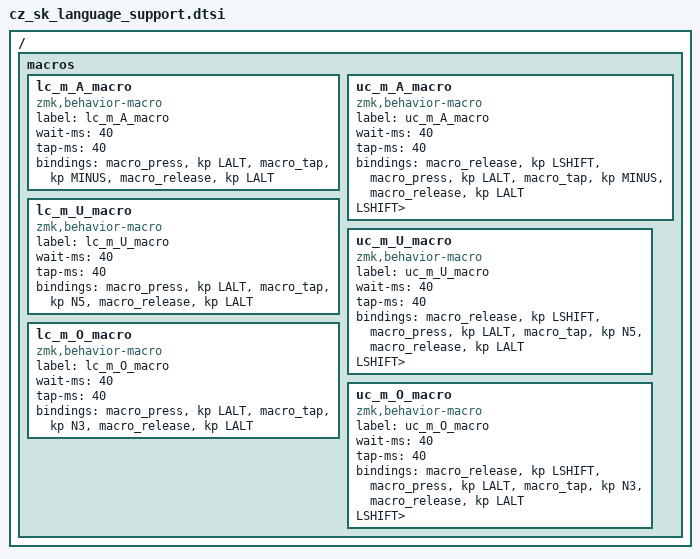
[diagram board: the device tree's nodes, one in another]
#include <dt-bindings/zmk/keys.h>

#pragma once

#define HELPER_STRINGIFY(x) #x

/****** LETTER MODIFIER MACROS ******/

/ {
    macros {

        lc_m_A_macro: lc_m_A_macro {
            label = "lc_m_A_macro";
            compatible = "zmk,behavior-macro";
            wait-ms = <40>;
            tap-ms = <40>;
            bindings =
                <&macro_press>,
                <&kp LALT>,
                <&macro_tap>,
                <&kp MINUS>,
                <&macro_release>,
                <&kp LALT>;
                <&macro_tap>,
                <&kp A>,
            #binding-cells = <0>;
        };

        uc_m_A_macro: uc_m_A_macro {
            label = "uc_m_A_macro";
            compatible = "zmk,behavior-macro";
            wait-ms = <40>;
            tap-ms = <40>;
            bindings =
                <&macro_release>,
                <&kp LSHIFT>,
                <&macro_press>,
                <&kp LALT>,
                <&macro_tap>,
                <&kp MINUS>,
                <&macro_release>,
                <&kp LALT>;
                <&macro_press>,
                <&kp LSHIFT>,
                <&macro_tap>,
                <&kp A>,
                <&macro_release>,
                <&kp LSHIFT>;
            #binding-cells = <0>;
        };

        lc_m_U_macro: lc_m_U_macro {
            label = "lc_m_U_macro";
            compatible = "zmk,behavior-macro";
            wait-ms = <40>;
            tap-ms = <40>;
            bindings =
                <&macro_press>,
                <&kp LALT>,
                <&macro_tap>,
                <&kp N5>,
                <&macro_release>,
                <&kp LALT>;
                <&macro_tap>,
                <&kp U>,
            #binding-cells = <0>;
        };

        uc_m_U_macro: uc_m_U_macro {
            label = "uc_m_U_macro";
            compatible = "zmk,behavior-macro";
            wait-ms = <40>;
            tap-ms = <40>;
            bindings =
                <&macro_release>,
                <&kp LSHIFT>,
                <&macro_press>,
                <&kp LALT>,
                <&macro_tap>,
                <&kp N5>,
                <&macro_release>,
                <&kp LALT>;
                <&macro_press>,
                <&kp LSHIFT>,
                <&macro_tap>,
                <&kp U>,
                <&macro_release>,
                <&kp LSHIFT>;
            #binding-cells = <0>;
        };

        lc_m_O_macro: lc_m_O_macro {
            label = "lc_m_O_macro";
            compatible = "zmk,behavior-macro";
            wait-ms = <40>;
            tap-ms = <40>;
            bindings =
                <&macro_press>,
                <&kp LALT>,
                <&macro_tap>,
                <&kp N3>,
                <&macro_release>,
                <&kp LALT>;
                <&macro_tap>,
                <&kp O>,
            #binding-cells = <0>;
        };

        uc_m_O_macro: uc_m_O_macro {
            label = "uc_m_O_macro";
            compatible = "zmk,behavior-macro";
            wait-ms = <40>;
            tap-ms = <40>;
            bindings =
                <&macro_release>,
                <&kp LSHIFT>,
                <&macro_press>,
                <&kp LALT>,
                <&macro_tap>,
                <&kp N3>,
                <&macro_release>,
                <&kp LALT>;
                <&macro_press>,
                <&kp LSHIFT>,
                <&macro_tap>,
                <&kp O>,
                <&macro_release>,
                <&kp LSHIFT>;
            #binding-cells = <0>;
        };
    };
};

#define UPPERCASE_LONG(letter) \
    / { \
        macros { \
            uc_l_ ## letter: uc_l_ ## letter { \
                label = HELPER_STRINGIFY(uc_l_ ## letter); \
                compatible = "zmk,behavior-macro"; \
                wait-ms = <40>; \
                tap-ms = <40>; \
                bindings = \
                    <&macro_release>, \
                    <&kp LSHIFT>, \
                    <&macro_tap>, \
                    <&kp EQUAL>, \
                    <&macro_press>, \
                    <&kp LSHIFT>, \
                    <&macro_tap>, \
                    <&kp letter>, \
                    <&macro_release>, \
                    <&kp LSHIFT>; \
                #binding-cells = <0>; \
                }; \
        }; \
    };

#define LOWERCASE_LONG(letter) \
    / { \
        macros { \
            lc_l_ ## letter: lc_l_ ## letter { \
                label = HELPER_STRINGIFY(lc_l_ ## letter); \
                compatible = "zmk,behavior-macro"; \
                wait-ms = <40>; \
                tap-ms = <40>; \
                bindings = \
                    <&macro_tap>, \
                    <&kp EQUAL>, \
                    <&macro_tap>, \
                    <&kp letter>; \
                #binding-cells = <0>; \
                }; \
        }; \
    };

#define UPPERCASE_SOFT(letter) \
    / { \
        macros { \
            uc_s_ ## letter: uc_s_ ## letter { \
                label = HELPER_STRINGIFY(uc_s_ ## letter); \
                compatible = "zmk,behavior-macro"; \
                wait-ms = <40>; \
                tap-ms = <40>; \
                bindings = \
                    <&macro_press>, \
                    <&kp LSHIFT>, \
                    <&macro_tap>, \
                    <&kp EQUAL>, \
                    <&macro_tap>, \
                    <&kp letter>, \
                    <&macro_release>, \
                    <&kp LSHIFT>; \
                #binding-cells = <0>; \
                }; \
        }; \
    };

#define LOWERCASE_SOFT(letter) \
    / { \
        macros { \
            lc_s_ ## letter: lc_s_ ## letter { \
                label = HELPER_STRINGIFY(lc_s_ ## letter); \
                compatible = "zmk,behavior-macro"; \
                wait-ms = <40>; \
                tap-ms = <40>; \
                bindings = \
                    <&macro_press>, \
                    <&kp LSHIFT>, \
                    <&macro_tap>, \
                    <&kp EQUAL>, \
                    <&macro_release>, \
                    <&kp LSHIFT>; \
                    <&macro_tap>, \
                    <&kp letter>; \
                #binding-cells = <0>; \
                }; \
        }; \
    };


/****** KEY DEFINITIONS ******/

LOWERCASE_LONG(A)                       // lowercase A long     - á
UPPERCASE_LONG(A)                       // uppercase A long     - Á
#define lc_m_A lc_m_A_macro             // lowercase A miscellenaous  - ä
#define uc_m_A uc_m_A_macro             // uppercase A miscellenaous  - Ä

LOWERCASE_LONG(E)                       // lowercase E long     - é
UPPERCASE_LONG(E)                       // uppercase E long     - É
LOWERCASE_SOFT(E)                       // lowercase E soft     - ě  
UPPERCASE_SOFT(E)                       // uppercase E soft     - Ě

LOWERCASE_LONG(I)                       // lowercase I long     - í
UPPERCASE_LONG(I)                       // uppercase I long     - Í

LOWERCASE_LONG(O)                       // lowercase O long     - ó
UPPERCASE_LONG(O)                       // uppercase O long     - Ó
#define lc_m_o lc_m_O_macro             // lowercase O miscellenaous  - ô
#define uc_m_o uc_m_O_macro             // uppercase O miscellenaous  - Ô

LOWERCASE_LONG(U)                       // lowercase U long     - ú
UPPERCASE_LONG(U)                       // uppercase U long     - Ú
#define lc_m_U lc_m_U_macro             // lowercase U miscellenaous  - ů
#define uc_m_U uc_m_U_macro             // uppercase U miscellenaous  - Ů

LOWERCASE_LONG(Y)                       // lowercase Y long     - ý
UPPERCASE_LONG(Y)                       // uppercase Y long     - Ý

LOWERCASE_SOFT(S)                       // lowercase S soft     - š
UPPERCASE_SOFT(S)                       // uppercase S soft     - Š

LOWERCASE_SOFT(T)                       // lowercase T soft     - ť
UPPERCASE_SOFT(T)                       // uppercase T soft     - Ť

LOWERCASE_SOFT(Z)                       // lowercase Z soft     - ž
UPPERCASE_SOFT(Z)                       // uppercase Z soft     - Ž

LOWERCASE_SOFT(D)                       // lowercase D soft     - ď
UPPERCASE_SOFT(D)                       // uppercase D soft     - Ď

LOWERCASE_SOFT(C)                       // lowercase C soft     - č
UPPERCASE_SOFT(C)                       // uppercase C soft     - Č

LOWERCASE_SOFT(N)                       // lowercase N soft     - ň
UPPERCASE_SOFT(N)                       // uppercase N soft     - Ň

LOWERCASE_LONG(L)                       // lowercase L long     - ĺ
UPPERCASE_LONG(L)                       // uppercase L long     - Ĺ
LOWERCASE_SOFT(L)                       // lowercase L soft     - ľ  
UPPERCASE_SOFT(L)                       // uppercase L soft     - Ľ

LOWERCASE_LONG(R)                       // lowercase R long     - ŕ
UPPERCASE_LONG(R)                       // uppercase R long     - Ŕ
LOWERCASE_SOFT(R)                       // lowercase R soft     - ř
UPPERCASE_SOFT(R)                       // uppercase R soft     - Ř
